# CY8C4xxx register map
File version: 0.1
Registers are 8-bit, read-write, no defined reset value unless marked. A register's access mark holds for its fields unless they carry their own. Offsets are from the block's base; [hi:lo] are bit positions; {n}, {i} and the like mark numbered series; 'fields as' and 'values as' point back to an identical list; <NAME> marks a mode.

## SRSS — SRSSv2 Registers (Power, Clock, Reset)
Base 0x400B0000
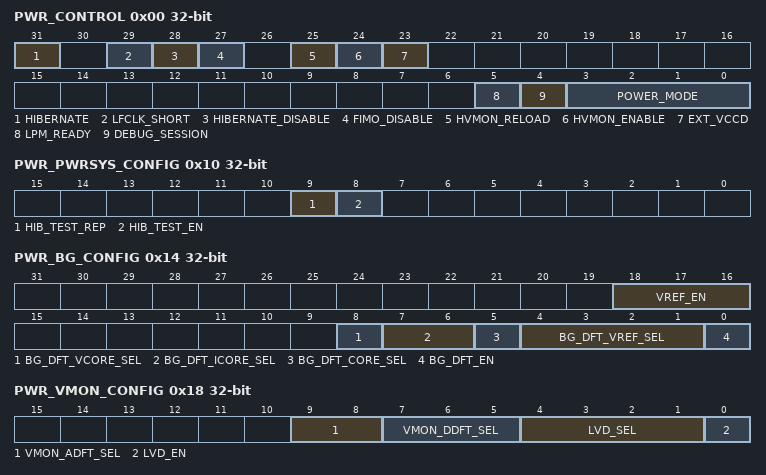
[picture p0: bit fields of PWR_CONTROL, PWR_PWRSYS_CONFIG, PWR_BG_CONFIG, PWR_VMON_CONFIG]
0x00 PWR_CONTROL 32-bit — Power Mode Control
  [31] HIBERNATE — Selects between HIBERNATE/DEEPSLEEP modes when Cortex-M0 enters low power mode (SleepDeep). Note: this bit is ignored when HIBERNATE_DISABLE=1.
    0=DEEP_SLEEP; 1=HIBERNATE
  [29] LFCLK_SHORT — Short Vcclfclk and Vccdpslp power rails in DeepSleep power mode. This mode selection affects the accuracy specifications of the ILO oscillator due to supply noise. See Data Sheet for more details.?0: Do not short power domains?1: Short power domains
  [28] HIBERNATE_DISABLE write-once — 0: Normal operation, HIBERNATE works as described?1: HIBERNATE bit is ignored, Hibernate mode is permanently disabled (part will go to DeepSleep instead.?Note: This bit is a write-once bit until the next reset.
  [27] FIMO_DISABLE — This bit is asserted during the boot process?0: Forces IMO to operate at 12MHz, ignore its frequency and trim settings and operate independent on its external references.?1: Turns IMO into normal operational mode
  [25] HVMON_RELOAD write-once — Firmware writes 1 to reload HV State in hibernate shadow copy. Hardware clears this bit after reload was successful.
  [24] HVMON_ENABLE — 0: HV State Monitoring is disabled?1: HV State Monitoring is automatically enable by sleep controller
  [23] EXT_VCCD — Indicates that Vccd is provided externally (on Vccd pin). Setting this bit turns off the active regulator and will lead to system reset (PBOD) unless both Vddd and Vccd pins are supplied externally.
  [5] LPM_READY ro — Indicates whether the low power mode regulators are ready to enter DEEPSLEEP or HIBERNATE mode. ?0: If DEEPSLEEP or HIBERNATE mode is requested, device will enter SLEEP mode. When low power regulators are ready, device will automatically enter the originally requested mode.?1: Normal operation. DEEPSLEEP and HIBERNATE work as described.
  [4] DEBUG_SESSION ro — Indicates whether a debug session is active (CDBGPWRUPREQ signal is 1)
    0=NO_SESSION; 1=SESSION_ACTIVE
  [3:0] POWER_MODE ro — Current power mode of the device. Note that this field cannot be read in all power modes on actual silicon.
    0=RESET; 1=ACTIVE; 2=SLEEP; 3=DEEP_SLEEP; 4=HIBERNATE
0x04 PWR_INTR 32-bit — Power System Interrupt Register
  [1] LVD write-once — Indicates an Low Voltage Detect interrupt
0x08 PWR_INTR_MASK 32-bit — Power System Interrupt Mask Register
  [1] LVD — 1: Propagate interrupt to CPU
0x0C PWR_KEY_DELAY 32-bit — Power System Key&Delay Register
  [9:0] WAKEUP_HOLDOFF — Delay (in 12MHz IMO clock cycles) to wait for references to settle on wakeup from hibernate/deepsleep. PBOD is ignored and system does not resume until this delay expires. Note that the same delay on POR is hard-coded.
0x10 PWR_PWRSYS_CONFIG 32-bit — Power System Trim and Configuration
  [9] HIB_TEST_REP — When set the enhanced replica load regulation circuit is enabled. When clear, the enhancments are disabled at the cost of higher current. (engineering only)
  [8] HIB_TEST_EN — Bias control for the DSBOD/HBOD. (engineering only)?0: low power biasing?1: turbo biasing
0x14 PWR_BG_CONFIG 32-bit — Bandgap Trim and Configuration
  [18:16] VREF_EN — Reference voltage enable. Each bit enables a reference voltage used by a peripheral.
  [8] BG_DFT_VCORE_SEL — ADFT mux select for Bandgap characterization (engineering only). Selects a BG core voltage to output on mux2out?0=vout?1=vgnd
  [7:6] BG_DFT_ICORE_SEL — ADFT mux select for Bandgap characterization (engineering only). Selects a BG core current to output on mux1out?0=iptat (current?1=ictat (current)?2=inl_cross_over detect (voltage)?3=iref9p6u_dft (dedicated output for DFT)?Also selects a currect for iref_dft (when BG_DFT_VREF_SEL=13)?0=iref2p4u[1]?1=iptat2p4u[7]?2=iref_imo (9.6uA current output from IMO IBG)?3=iref3u_dft (dedicated output for DFT)
  [5] BG_DFT_CORE_SEL — ADFT mux select for Bandgap characterization (engineering only). Selects which BG core signal to output on adft_bg_core?0=BG core voltage selected by BG_DFT_VCORE_SEL (mux2out)?1=BG core current selected by BG_DFT_ICORE_SEL (mux1out)
  [4:1] BG_DFT_VREF_SEL — ADFT mux select for Reference System characterization (engineering only). Select a voltage reference to output on adft_bg_ref?0=vgnd?1=vref_fast[0]?2=vref_fast[1]?3=vref_fast[2]?4=vref_fast[3]?5=vref_fast[4]?6=vref_fast[5]?7=vref_fast[6]?8=vref_fast[7]?9=vref[0]?10=vref[1]?11=vref[2]?12=vctat?13=iref_dft (see BG_DFT_ICORE_SEL)?14=imo_iref (current)?15=inl_imoref (voltage)
  [0] BG_DFT_EN — Enables DFT capability for Bandgap. (engineering only)
0x18 PWR_VMON_CONFIG 32-bit — Voltage Monitoring Trim and Configuration
  [9:8] VMON_ADFT_SEL — ADFT mux select for HVPOR, PBOD, and LVD circuits (engineering only). Selects a signal to output on adft_vmon?0: Hi-Z?1: Comparator Input of pbod Monitor?2: Comparator Input of hvpbod Monitor?3: Comparator Input of lvi Monitor
  [7:5] VMON_DDFT_SEL — DDFT mux select for HVPOR, PBOD, and LVD circuits (engineering only). Selects a signal to output on adft_vmon?0: 0?1: pbod_out?2: Pulse Strecher output of pbod Monitor?3: hvpbod_out?4: Pulse Strecher output of hvpbod Monitor?5: lvi_out?6: Pulse Strecher output of lvi Monitor?7: 0
  [4:1] LVD_SEL — Threshold selection for Low Voltage Detect circuit. Threshold variation is +/- 2.5% from these typical voltage choices:?0: 1.7500 V?1: 1.8000 V?2: 1.9000 V?3: 2.0000 V?4: 2.1000 V?5: 2.2000 V?6: 2.3000 V?7: 2.4000 V?8: 2.5000 V?9: 2.6000 V?10: 2.7000 V?11: 2.8000 V?12: 2.9000 V?13: 3.0000 V?14: 3.2000 V?15: 4.5000 V
  [0] LVD_EN — Enable Low Voltage Detect circuit.
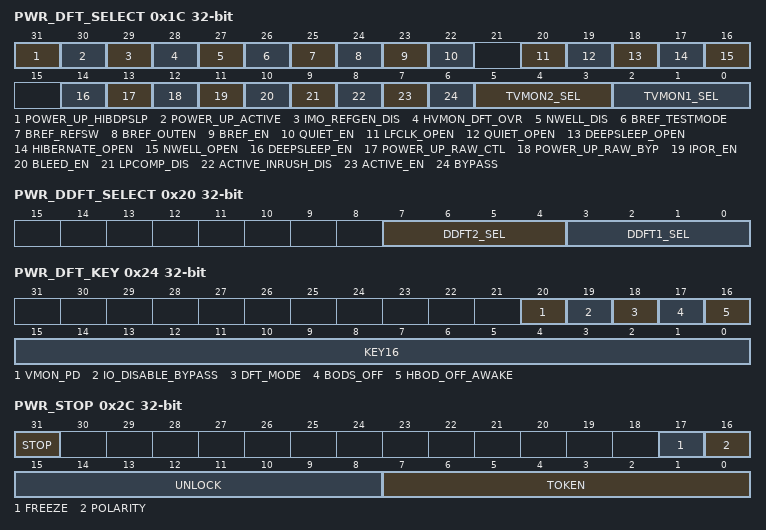
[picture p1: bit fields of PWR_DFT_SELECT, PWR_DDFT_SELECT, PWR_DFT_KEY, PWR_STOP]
0x1C PWR_DFT_SELECT 32-bit — Power DFT Mode Selection Register
  [31] POWER_UP_HIBDPSLP — When set, forces pwrg_actdig=1 for hibernate/deepsleep circuits. Combined with POWER_UP_RAW_CTL=0, this gives full control on this input for characterization and testing.
  [30] POWER_UP_ACTIVE — When set, forces pwrgood=1 for active regulator. Combined with POWER_UP_RAW_CTL=0, this gives full control on this input for characterization and testing.
  [29] IMO_REFGEN_DIS — Disables the IMO reference generator to allow testing the current references. A side-effect of setting this bit is that the SRSS outputs vbias_ptat and vbias_casc_ptat are shorted to vccq.
  [28] HVMON_DFT_OVR — Overrides the trim values coming from NVLatches to the values stored in the HV Monitor. Allows char & test of the NVLatches without disturbing trims.
  [27] NWELL_DIS — Controls the vnwell level during deep sleep and hibernate. When set, the nwell regulator is disabled. When this bit is set, the Vnwell rail will be shorted to Vcchib rail (nwell_short).
  [26] BREF_TESTMODE — Puts the bootref in testmode. Intended for characterization and testing.
  [25] BREF_REFSW — Controls the power system reference source?0: boot reference?1: Low voltage bandgap (LVBG)?Using the LVBG reference improves PSRR. Only works when BYPASS=1. Intended for characterization and testing.
  [24] BREF_OUTEN — Enables the output stage of the LDO reference selector. Do not clear this bit when the active regulator is operating. Only works when BYPASS=1. Intended for characterization and testing.
  [23] BREF_EN — Enables the boot reference currents. Do not clear this bit unless he active regulator, quiet regulator, or LPCOMP are bypassed. Only works when BYPASS=1. Intended for characterization and testing.
  [22] QUIET_EN — Force Vccq regulator on/off. Only works when BYPASS=1. Intended for IDDQ testing.
  [20] LFCLK_OPEN — Force switch between Vcclfclk and Vccdpslp open. Only works when BYPASS=1. Intended for IDDQ testing.
  [19] QUIET_OPEN — Force switch between Vccq and Vccdpslp open. Only works when BYPASS=1. Intended for IDDQ testing.
  [18] DEEPSLEEP_OPEN — Force switch between Vccdpslp and Vccd open. Only works when BYPASS=1. Intended for IDDQ testing.
  [17] HIBERNATE_OPEN — Force switch between Vcchib and Vccdpslp open. Only works when BYPASS=1, PWR_DFT_KEY.KEY16 is set to the key, and PWR_DFT_KEY.DFT_MODE=1. Intended for IDDQ testing.
  [16] NWELL_OPEN — Force switch between Vnwell and Vcchib open. Only works when BYPASS=1. Intended for IDDQ testing.
  [14] DEEPSLEEP_EN — Force DeepSleep Regulator on. Only works when BYPASS=1. Intended for DeepSleep Regulator IDDQ testing.
  [13] POWER_UP_RAW_CTL — Value to force onto power_up_raw_hv. Only works when POWER_UP_RAW_BYP=1.
  [12] POWER_UP_RAW_BYP — When set, the LPCOMP output is controllable by POWER_UP_RAW_CTL. Only works when BYPASS=1. Intended for testing quiet regulator delayline, active regulator, and hibernate/deepsleep regulator.
  [11] IPOR_EN — Force IPOR_EN signal high. Only works when BYPASS=1. Intended for IPOR/HVPOR IDDQ testing. You must bypass the IO cells using PWR_DFT_KEY.IO_DISABLE_BYPASS and .KEY16 before setting this bit.
  [10] BLEED_EN — When set enables bleeder cells on various switched power nets to accelerate discharge during retention testing.
  [9] LPCOMP_DIS — When set disables the LPCOMP. Only do this when the LPCOMP outputs are properly bypassed using the POWER_UP_* bits and also PWR_DFT_KEY.DFT_MODE=1. Only works when BYPASS=1. Intended for LPCOMP testing.
  [8] ACTIVE_INRUSH_DIS — Force disable of active regulator inrush current limiter. Only works when BYPASS=1. Intended for characterization and testing.
  [7] ACTIVE_EN — Force active regulator on. Only works when BYPASS=1. Intended for characterization and testing.
  [6] BYPASS — Forces regulator into bypass mode. Disables active mode regulator and allows most switches and other regulators to be manually controlled though other bits in this register..
  [5:3] TVMON2_SEL — Select source for PWRSYS ADFT output #2:?0: not connected (default)?1: not connected?2: Boot Reference biasn?3: Boot Reference nprot?4: DO NOT USE. Unsafely diode couples vccd_sw to bootref 800mV reference.?5: Boot Reference 800mv?6: not connected?7: not connected
  [2:0] TVMON1_SEL — Select source for PWRSYS ADFT output #1:?0: not connected (default)?1: vnwell?2: vccq?3: vccd_sw?4: vcclfclk?5: vcchib?6: vccdpslp?7: vccqr
0x20 PWR_DDFT_SELECT 32-bit — Digital DFT Select
  [7:4] DDFT2_SEL — Signal select for ddft2 output:?0: act_power_en_a?1: power_up_raw?2: act_power_good_a?3: fastrefs_valid?4: vmon?5: bootref_outen?6: bootref_refsw?7: active_inrush_dis?8: awake?9: hvpor_reset_n?10: lpcomp_dis?11: wakeup_a?12: vmon_valid?13: block_rst_awake?14: slpholdreq_n?15: io_disable_delayed
  [3:0] DDFT1_SEL — Signal select for ddft1 output:?0: wakeup_a?1: ipor_reset?2: hbod_reset_raw_n?3: lpcomp_dis?4: power_up_delayed?5: awake?6: hvmon_out_of_sync?7: pbod_reset?8: hvbod_reset?9: lpm_ready?10: io_disable_req_lv (excluding por_force_in_hv)?11: bootref_en
0x24 PWR_DFT_KEY 32-bit — DFT Safety Override
  [20] VMON_PD — Disables the VMON block, which includes PBOD, HVBOD, and LVD circuits. Set BODS_OFF=1 in a previous write cycle to prevent an unintended reset.
  [19] IO_DISABLE_BYPASS — Bypasses the IO disable logic for testing the delay-line that is part of the glitch-free IO reset circuitry. Internally, prevents the outputs from getting disabled (io_disable_req_hv=0) and blocks resets (io_disable_ack_hv=0). The delay-line continues to function and can be routed to DDFT for testing.
  [18] DFT_MODE — Enable DfT modes other than the above. Currently gates power_up comparator for characterization.
  [17] BODS_OFF — Forces all outputs of BOD detectors to be ignored, effectively disabling all brown-out detection. Can be used in conjunction with DDFT to test the detectors without triggering reset.
  [16] HBOD_OFF_AWAKE — Forces the output of the HBOD to be blocked (ignored) while in Active or Sleep mode (i.e. when under the umbrella of PBOD).
  [15:0] KEY16 — This field must be set to 0xE4C5 for any of the other fields in this register to have effect and for scan_mode to be allowed. When this fields has any other value, all other fields in this register are ignored and assumed to be 0 by the hardware, and scan_mode is ignored inside the power generation system. It is assumed that this register will always be set to 0xE4C5 before entering scan.
0x28 PWR_BOD_KEY 32-bit — BOD Detection Key
  [15:0] KEY16 — To detect brown-outs firmware should do this on boot:?1. Set key= KEY16?2. Set KEY16= 0x3A71?3. If key==0x3A71 this was a brown-out event.
0x2C PWR_STOP 32-bit — STOP Mode Register
  [31] STOP — Firmware sets this bit to enter STOP mode. Both UNLOCK and FREEZE must have been set correctly in a previous write operation. Otherwise, writes to this bit will affect the freeze override but will not actually set the STOP bit. The system will enter STOP mode immediately after writing to this bit and will wakeup only in response to XRES or WAKEUP event.
  [17] FREEZE — Firmware sets this bit to freeze the configuration, mode and state of all GPIOs and SIOs in the system. Two identical write cycles are required to freeze the IO explicitly. The first cycle instructs DEEPSLEEP and HIBERNATE peripherals whether they can override upcoming freeze command(s). UNLOCK setting does not affect this. If firmware writes FREEZE=1 and STOP=0, peripherals can override the freeze and remain functional according to their configuration. If firmware writes FREEZE=1 and STOP=1, peripherals cannot override the next freeze command. The second write cycle freezes the IO if UNLOCK is set and the peripheral does not override the freeze. While FREEZE=1, peripherals will automatically freeze according to the override directive when entering DEEPSLEEP or HIBERNATE, regardless of the UNLOCK setting.
  [16] POLARITY — 0: WAKEUP=0 will wakeup the part from STOP?1: WAKEUP=1 will wakeup the part from STOP
  [15:8] UNLOCK — This byte must be set to 0x3A for FREEZE or STOP fields to operate. Any other value in this register will cause FREEZE/STOP to have no effect, except as noted in the FREEZE description.
  [7:0] TOKEN — Contains a 8-bit token that is retained through a STOP/WAKEUP sequence that can be used by firmware to differentiate WAKEUP from a general RESET event. Note that waking up from STOP using XRES will reset this register.
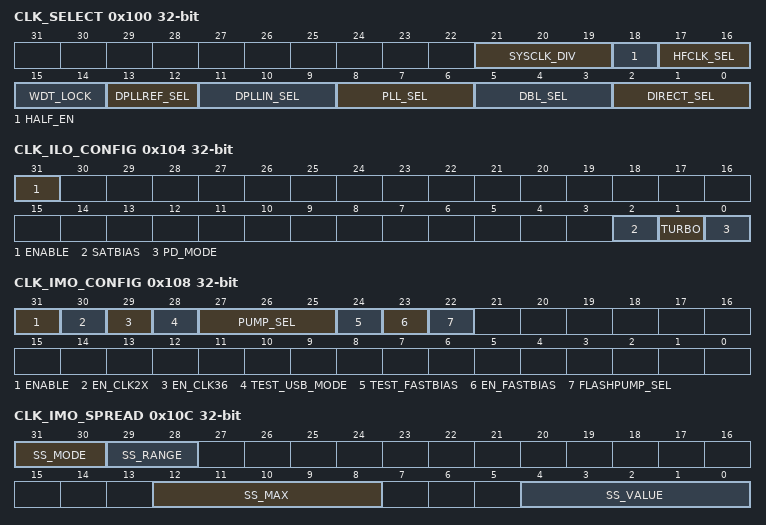
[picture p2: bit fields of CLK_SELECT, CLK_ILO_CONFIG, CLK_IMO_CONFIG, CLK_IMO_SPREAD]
0x100 CLK_SELECT 32-bit — Clock Select Register
  [21:19] SYSCLK_DIV — SYSCLK Pre-Scaler Value.
    0=NO_DIV; 1=DIV_BY_2; 2=DIV_BY_4; 3=DIV_BY_8; 4=DIV_BY_16; 5=DIV_BY_32; 6=DIV_BY_64; 7=DIV_BY_128
  [18] HALF_EN — This bit impact products using CPUSSv1 only. It has no effect on products using CPUSSv2.?FLASH Wait-state selection. This must be set to 1 when clk_sys is set to a frequency greater than 24MHz.?0: Access FLASH using 0 wait-states. Only use this setting when HFCLK is <=24MHz.?1: Access FLASH using 1 wait-state. Safe to use this setting for any clock frequency.
  [17:16] HFCLK_SEL — Selects the source for HFCLK.
    0=DIRECT_SEL; 1=DBL; 2=PLL
  [15:14] WDT_LOCK — Prohibits writing to WDT_* registers and CLK_ILO/WCO_CONFIG registerst when not equal 0. Requires at least two different writes to unlock.?Note that this field is 2 bits to force multiple writes only. It represents only a single write protect signal protecting all WATCHDOG registers at the same time.
    0=NO_CHG; 1=CLR0; 2=CLR1; 3=SET01
  [13:12] DPLLREF_SEL — Selects a source for the reference (tracking) input of DPLL:?0: DSI_OUT[0]?1: DSI_OUT[1]?2: DSI_OUT[2]?3: DSI_OUT[3]
    {v}=DSI{v} (v=0..3)
  [11:9] DPLLIN_SEL — Selects a source for the input of DPLL.?Note that not all products support all clock sources. Selecting a clock source that is not supported will result in undefined behavior.
    0=IMO; 1=EXTCLK; 2=ECO; {v}=DSI{v-4} (v=4..7)
  [8:6] PLL_SEL — Selects a source for the input of the PLL.?Note that not all products support all clock sources. Selecting a clock source that is not supported will result in undefined behavior.
    0=IMO; 1=EXTCLK; 2=ECO; 3=DPLL; {v}=DSI{v-4} (v=4..7)
  [5:3] DBL_SEL — Selects a source for the input of DBL.?Note that not all products support all clock sources. Selecting a clock source that is not supported will result in undefined behavior.
    0=IMO; 1=EXTCLK; 2=ECO; {v}=DSI{v-4} (v=4..7)
  [2:0] DIRECT_SEL — Selects a source for HFCLK (when HFCLK_SEL=0) and DSI_IN[0].?Note that not all products support all clock sources. Selecting a clock source that is not supported will result in undefined behavior.?Note that using DSI_OUT[3:0] as HFCLK source will also result in undefined behavior. These values are available strictly to provide a clock in DSI_IN[0].
    0=IMO; 1=EXTCLK; 2=ECO; {v}=DSI{v-4} (v=4..7)
0x104 CLK_ILO_CONFIG 32-bit — ILO Configuration
  [31] ENABLE — Master enable for ILO oscillator
  [2] SATBIAS — PFET bias
    0=SATURATED; 1=SUBTHRESHOLD
  [1] TURBO — Turbo mode for faster startup from coma power down?0: turbo disabled?1: turbo enabled
  [0] PD_MODE — Power down mode. Note: this bit must always be set to 0 and never changed. Behavior is undefined when set to 1.
    0=SLEEP; 1=COMA
0x108 CLK_IMO_CONFIG 32-bit — IMO Configuration
  [31] ENABLE — Master enable for IMO oscillator. Clearing this bit will disable the IMO but not disconnect it from the power rail. This bit can also be used during IDDQ testing.
  [30] EN_CLK2X — Enables main oscillator doubler circuit that can be used for TSS Charge Pumps. This circuit is not available to generate any digital clocks.
  [29] EN_CLK36 — Enables 36MHz secondary oscillator that can be used for Pump or Flash Pump. Note: Since there are two consumers of the 36MHz clock, care should be taken when clearing this bit. The correct procedure for clearing this bit is:?1. Disable interrupts?2. Check if both FLASHPUMP_SEL<>1 and PUMP_SEL<>3?3. If so, set EN_CLK36=0?4. Enable interrupts
  [28] TEST_USB_MODE — Forces IMO into USB mode. Engineering only.?1: Software can write FSOFFSET, OFFSET, and GAIN settings for characterization. Hardware updates to these registers are not blocked, so disable USB peripheral updates if they are not desired.?0: Normal operation. IMO operates in either USB or non-USB mode, depending on the USB peripheral setting.
  [27:25] PUMP_SEL — Selects operating source for Pump clock. This clock is not guaranteed to be glitch free when changing IMO parameters or clock divider settings.?5-7: reserved, do not use
    0=GND; 1=IMO; 2=DBL; 3=CLK36; 4=FF1
  [24] TEST_FASTBIAS — Forces the IMO into FIMO mode (engineering only). Only works when EN_FASTBIAS=1.
  [23] EN_FASTBIAS — Forces the FIMO's fast bias circuits to remain powered (engineering only). This bit must be cleared by BootROM after FIMO is no longer required.
  [22] FLASHPUMP_SEL — Selects operating source for SPCIF Timer/Flash Pump clock.
    0=GND; 1=CLK36
0x10C CLK_IMO_SPREAD 32-bit — IMO Spread Spectrum Configuration
  [31:30] SS_MODE — Spread Spectrum Mode.
    0=OFF; 1=TRIANGLE; 2=LFSR; 3=DSI
  [29:28] SS_RANGE — Spread spectrum range (downspread when SS_VALUE=16).?3: reserved, do not use
    0=M1; 1=M2; 2=M4
  [12:8] SS_MAX — Maximum counter value for spread spectrum. Counter will count from 0..SS_MAX..0 and keep repeating this indefinitely. Only works when SS_MODE=1.
  [4:0] SS_VALUE — Current offset value for spread spectrum modulation. IMO supports values 0..16. Step size is determined by SS_RANGE. Value is encoded in proper thermometric format for IMO in hardware. Value can be modified in firmware only when SS_MODE=0.
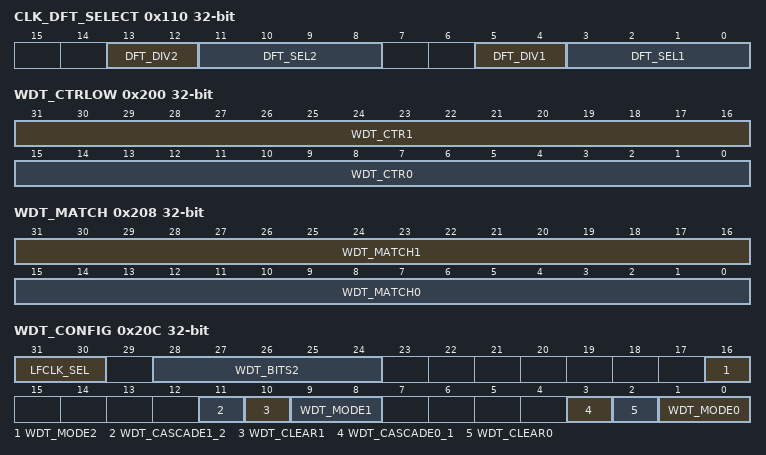
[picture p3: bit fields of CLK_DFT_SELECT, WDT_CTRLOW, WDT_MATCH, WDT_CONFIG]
0x110 CLK_DFT_SELECT 32-bit — Clock DFT Mode Selection Register
  [13:12] DFT_DIV2 — DFT Output Divide Down.
    0=NO_DIV; 1=DIV_BY_2; 2=DIV_BY_4; 3=DIV_BY_8
  [11:8] DFT_SEL2 — Select signal for DFT output #2.
    0=NC; 1=ILO; 2=WCO; 3=IMO; 4=ECO; 5=PLL; 6=DPLL_OUT; 7=DPLL_REF; 8=DBL; 9=IMO2X; 10=IMO36; 11=HFCLK; 12=LFCLK; 13=SYSCLK; 14=EXTCLK; 15=HALFSYSCLK
  [5:4] DFT_DIV1 — DFT Output Divide Down.
    0=NO_DIV; 1=DIV_BY_2; 2=DIV_BY_4; 3=DIV_BY_8
  [3:0] DFT_SEL1 — Select signal for DFT output #1.
    values as DFT_SEL2
0x200 WDT_CTRLOW 32-bit — Watchdog Counters 0/1
  [31:16] WDT_CTR1 ro — Current value of WDT Counter 1
  [15:0] WDT_CTR0 ro — Current value of WDT Counter 0
0x204 WDT_CTRHIGH 32-bit — Watchdog Counter 2
  [31:0] WDT_CTR2 ro — Current value of WDT Counter 2
0x208 WDT_MATCH 32-bit — Watchdog counter match values
  [31:16] WDT_MATCH1 — Match value for Watchdog Counter 1
  [15:0] WDT_MATCH0 — Match value for Watchdog Counter 0
0x20C WDT_CONFIG 32-bit — Watchdog Counters Configuration
  [31:30] LFCLK_SEL — Select source for LFCLK:?0: ILO - Internal R/C Oscillator?1: WCO - Internal Crystal Oscillator?2-3: Reserved - do not use?Note that not all products support all clock sources. Selecting a clock source that is not supported will result in undefined behavior.
  [28:24] WDT_BITS2 — Bit to observe for WDT_INT2:?0: Assert when bit0 of WDT_CTR2 toggles (one int every tick)?..?31: Assert when bit31 of WDT_CTR2 toggles (one int every 2^31 ticks)
  [16] WDT_MODE2 — Watchdog Counter 2 Mode.
    0=NOTHING; 1=INT
  [11] WDT_CASCADE1_2 — Cascade Watchdog Counters 1,2. Counter 2 increments the cycle after WDT_CTR1=WDT_MATCH1. It is allowed to cascade all three WDT counters.?0: Independent counters?1: Cascaded counters
  [10] WDT_CLEAR1 — Clear Watchdog Counter when WDT_CTR1=WDT_MATCH1. In other words WDT_CTR1 divides LFCLK by (WDT_MATCH1+1).?0: Free running counter?1: Clear on match
  [9:8] WDT_MODE1 — Watchdog Counter Action on Match (WDT_CTR1=WDT_MATCH1).
    0=NOTHING; 1=INT; 2=RESET; 3=INT_THEN_RESET
  [3] WDT_CASCADE0_1 — Cascade Watchdog Counters 0,1. Counter 1 increments the cycle after WDT_CTR0=WDT_MATCH0.?0: Independent counters?1: Cascaded counters
  [2] WDT_CLEAR0 — Clear Watchdog Counter when WDT_CTR0=WDT_MATCH0. In other words WDT_CTR0 divides LFCLK by (WDT_MATCH0+1).?0: Free running counter?1: Clear on match
  [1:0] WDT_MODE0 — Watchdog Counter Action on Match (WDT_CTR0=WDT_MATCH0).
    0=NOTHING; 1=INT; 2=RESET; 3=INT_THEN_RESET
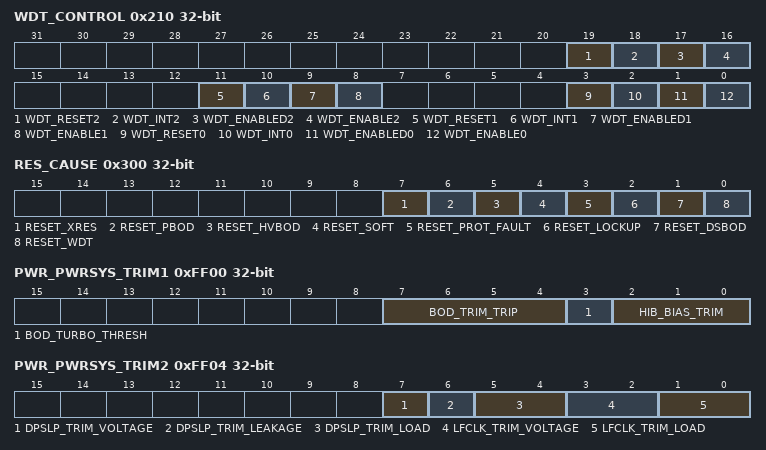
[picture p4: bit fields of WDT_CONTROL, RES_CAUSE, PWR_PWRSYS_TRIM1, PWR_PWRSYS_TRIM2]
0x210 WDT_CONTROL 32-bit — Watchdog Counters Control
  [19] WDT_RESET2 write-once — Resets counter 2 back to 0000_0000. Hardware will reset this bit after counter was reset. This will take several LFCLK cycles to take effect.
  [18] WDT_INT2 write-once — WDT Interrupt Request. This bit is set by hardware as configured by this registers. This bit must be cleared by firmware.
  [17] WDT_ENABLED2 ro — Indicates actual state of counter. May lag WDT_ENABLE2 by up to 3 LFCLK cycles.
  [16] WDT_ENABLE2 — Enable Counter 2?0: Counter is disabled (not clocked)?1: Counter is enabled (counting up)?Note: This field takes considerable time (up to 3 LFCLK cycles) to take effect. It must not be changed more than once in that period.
  [11] WDT_RESET1 write-once — Resets counter 1 back to 0000. Hardware will reset this bit after counter was reset. This will take several LFCLK cycles to take effect.
  [10] WDT_INT1 write-once — WDT Interrupt Request. This bit is set by hardware as configured by this registers. This bit must be cleared by firmware. Clearing this bit also prevents Reset from happening when WDT_MODEx=3.
  [9] WDT_ENABLED1 ro — Indicates actual state of counter. May lag WDT_ENABLE1 by up to 3 LFCLK cycles.
  [8] WDT_ENABLE1 — Enable Counter 1?0: Counter is disabled (not clocked)?1: Counter is enabled (counting up)?Note: This field takes considerable time (up to 3 LFCLK cycles) to take effect. It must not be changed more than once in that period.
  [3] WDT_RESET0 write-once — Resets counter 0 back to 0000. Hardware will reset this bit after counter was reset. This will take several LFCLK cycles to take effect.
  [2] WDT_INT0 write-once — WDT Interrupt Request. This bit is set by hardware as configured by this registers. This bit must be cleared by firmware. Clearing this bit also prevents Reset from happening when WDT_MODEx=3.
  [1] WDT_ENABLED0 ro — Indicates actual state of counter. May lag WDT_ENABLE0 by up to 3 LFCLK cycles.
  [0] WDT_ENABLE0 — Enable Counter 0?0: Counter is disabled (not clocked)?1: Counter is enabled (counting up)?Note: This field takes considerable time (up to 3 LFCLK cycles) to take effect. It must not be changed more than once in that period.
0x300 RES_CAUSE 32-bit — Reset Cause Observation Register
  [7] RESET_XRES write-once — This field is deprecated and will always read 0.
  [6] RESET_PBOD write-once — This field is deprecated and will always read 0.
  [5] RESET_HVBOD write-once — This field is deprecated and will always read 0.
  [4] RESET_SOFT write-once — Cortex-M0 requested a system reset through it's SYSRESETREQ. This can be done via a debugger probe or in firmware.
  [3] RESET_PROT_FAULT write-once — A protection violation occurred that requires a RESET. This includes, but is not limited to, hitting a debug breakpoint while in Privileged Mode.
  [2] RESET_LOCKUP write-once — This field is deprecated and will always read 0. Cortex-M0 LOCKUP is no longer a reset source.
  [1] RESET_DSBOD write-once — This field is deprecated and will always read 0.
  [0] RESET_WDT write-once — A WatchDog Timer reset has occurred since last power cycle.
0xFF00 PWR_PWRSYS_TRIM1 32-bit — Power System Trim Register
  [7:4] BOD_TRIM_TRIP — BOD trip point trim. BOD_TRIM_TRIP[2] is ignored and controlled by hardware directly.?0X00: Default trim setting?0X01: Default trim setting - 30mV?0X10: Default trim setting + 30mV?0X11: Invalid Setting (Do Not Use)?1X00: Default trim setting + 90mV?1X01: Default trim setting + 60mV?1X10: Default trim setting + 120mV?1X11: Invalid Setting (Do Not Use)
  [3] BOD_TURBO_THRESH — BOD Turbo Threshold Control?0 Turbo Threshold is set to 100mV above BOD trip point?1 Turbo Threshold is set to 50mV above BOD trip point
  [2:0] HIB_BIAS_TRIM — Current reference trim. This is internally overridden to 3'b010 for startup during POR and STOP wakeup. Afterward, it uses this setting for hibernate and sleep.
0xFF04 PWR_PWRSYS_TRIM2 32-bit — Power System Trim Register
  [7] DPSLP_TRIM_VOLTAGE — Raise output voltage?1= regulator hibernate 200mV higher?0= nominal 1.4-1.6V range
  [6] DPSLP_TRIM_LEAKAGE — Enable Vcchib pass gate leakage control
  [5:4] DPSLP_TRIM_LOAD — Current load trim capability?00= Min current load capability?11= Max current load capability
  [3:2] LFCLK_TRIM_VOLTAGE — Output voltage trim?00= default ?01= Trim lfclk by -50mV?10= Trim lfclk by +50mV?11= illegal
  [1:0] LFCLK_TRIM_LOAD — Current load trim capability?00= Min current load capability?11= Max current load capability
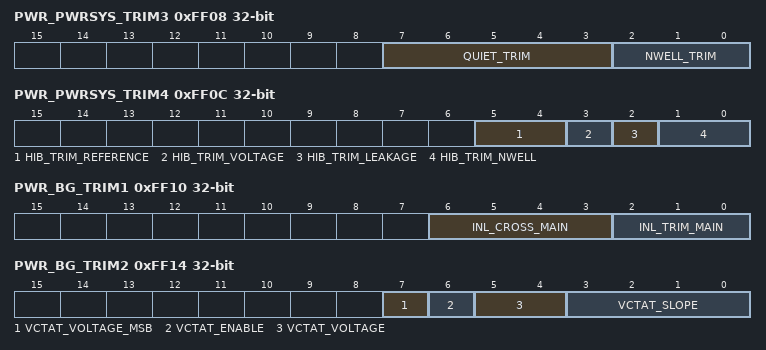
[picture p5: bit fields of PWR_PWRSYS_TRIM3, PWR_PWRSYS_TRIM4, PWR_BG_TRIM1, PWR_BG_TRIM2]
0xFF08 PWR_PWRSYS_TRIM3 32-bit — Power System Trim Register
  [7:3] QUIET_TRIM — Vccq (quiet regulator) trim
  [2:0] NWELL_TRIM — Vnwell (nwell regulator) trim?[0]: Vcchib + nhv(0.6V -1V)?[1]: Vcchib + nlowvt(0.4 -0.8V)?[2]: Vcchib + nhvnat(0.1-0.3)
0xFF0C PWR_PWRSYS_TRIM4 32-bit — Power System Trim Register
  [5:4] HIB_TRIM_REFERENCE — Hibernate Reference trim?10=Trim reference by -27mV?01=Trim reference by +27mV?00= no trim
  [3] HIB_TRIM_VOLTAGE — Elevate output voltage?1= regulator hibernate 200mV higher ?0= nominal 1.4-1.6V range
  [2] HIB_TRIM_LEAKAGE — Enable Vcchib pass gate leakage control
  [1:0] HIB_TRIM_NWELL — Vnwell Leakage control?00= smart nwell regulation?01= regulate nwell to constant voltage. ?10= regulate nwell to vcchib + nfet diode?11= regulate nwell to vcchib + nfet diode
0xFF10 PWR_BG_TRIM1 32-bit — Bandgap Trim Register
  [6:3] INL_CROSS_MAIN — Bandgap INL cross-over point control for centering curve at 30C (main current reference).
  [2:0] INL_TRIM_MAIN — Bandgap nonlinear current trim for curvature correction (main current reference).
0xFF14 PWR_BG_TRIM2 32-bit — Bandgap Trim Register
  [7] VCTAT_VOLTAGE_MSB — Output voltage absolute trim (MSB)
  [6] VCTAT_ENABLE — Enable VCTAT block
  [5:4] VCTAT_VOLTAGE — Output voltage absolute trim (LSBs). MSB is in VCTAT_VOLTAGE_MSB field.
  [3:0] VCTAT_SLOPE — Output slope setting controls. The slope of the voltage with temperature varies from ~0% to ~15% from the value at 55C over the temperature range -40C to 150C based on control signal settings 0 to 15
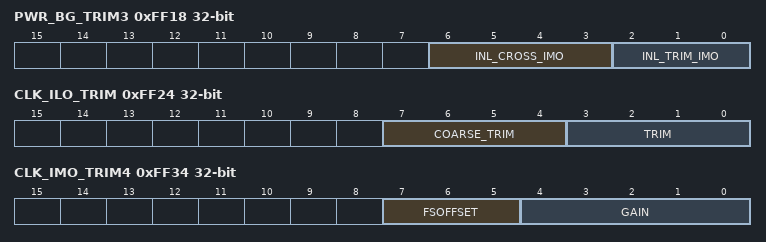
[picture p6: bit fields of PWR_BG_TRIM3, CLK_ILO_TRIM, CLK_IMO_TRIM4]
0xFF18 PWR_BG_TRIM3 32-bit — Bandgap Trim Register
  [6:3] INL_CROSS_IMO — IMO Irefgen INL cross-over point control for centering curve at 30C.
  [2:0] INL_TRIM_IMO — IMO Irefgen nonlinear current trim for curvature correction.
0xFF1C PWR_BG_TRIM4 32-bit — Bandgap Trim Register
  [5:0] ABS_TRIM_IMO — IMO-irefgen output current magnitude trim
0xFF20 PWR_BG_TRIM5 32-bit — Bandgap Trim Register
  [5:0] TMPCO_TRIM_IMO — IMO-irefgen output current temperature co-efficient trim
0xFF24 CLK_ILO_TRIM 32-bit — ILO Trim Register
  [7:4] COARSE_TRIM — Adjusts the bias in the event of high current after fab:?Bias trim:?bit3=0: Normal Mode?bit3=1:Low Current Mode??Resistor Trim (Short R to gnd):?bit2=0: Normal Mode?bit2=1: Short R/4?bit1=0: Unshort R/2?bit1=1: Normal Mode (Short R/2)?bit0=0: Unshort R/4?bit0=1: Normal Mode (Short 3R/4)
  [3:0] TRIM — Trim bits to control frequency?0: Minimum frequency?15: Maximum frequency
0xFF28 CLK_IMO_TRIM1 32-bit — IMO Trim Register
  [7:0] OFFSET — Frequency trim bits. These bits are determined at manufacturing time for each FREQ setting (IMO_TRIM2) and stored in SFLASH. This field is hardware updated during USB osclock mode.
0xFF2C CLK_IMO_TRIM2 32-bit — IMO Trim Register
  [5:0] FREQ — Frequency to be selected (default 24MHz). Frequencies can be selected from 3..48MHz. When changing this field approriate values for IMO_CLK_TRIM1, PWR_BG_TRIM4 and PWR_BG_TRIM5 must be selected from trim tables determined at manufacturing time and stored in SFLASH. This process is documented in the SAS under "Clocks - Selecting IMO Frequency". For encoding of this field a lookup table is required, where the frequency increases in 1MHz steps in the regions listed below. Unspecified values have undefined behavior. A complete lookup table is in BROS 001-59652 Sec 4.2.2. ?[3-12] => [3MHz-12MHz]?[14-25] => [13MHz-24MHz]?[27-35] => [25MHz-33MHz]?[37-43] => [34MHz-40MHz]?[46-53] => [41MHz-48MHz]
0xFF30 CLK_IMO_TRIM3 32-bit — IMO Trim Register
  [3:0] TRIM_CLK36 — Trim bits for 36MHz oscillator. Typically stored in SFLASH and copied here on boot.
0xFF34 CLK_IMO_TRIM4 32-bit — IMO Trim Register
  [7:5] FSOFFSET — Full-speed USB offset. Updated by hardware during USB osclock mode. Can be updated by software when TEST_USB_MODE=1. Otherwise writes are ignored. Engineering only.
  [4:0] GAIN — Gain for IMO. Typically stored in SFLASH and copied here on boot. Only used during USB mode, either during USB operation or when CLK_IMO_CONFIG.TEST_USB_MODE=1. When not in USB mode, this register is not used and the actual IMO gain is forced to a setting of 0.
0xFF38 PWR_RSVD_TRIM 32-bit — Reserved, unused registers
